# N32MC47x_DP47x register map
Vendor: Nsingtech Ltd.; File version: 1.0
Registers are 32-bit, read-write, reset 0x0 unless marked. A register's access mark holds for its fields unless they carry their own. Offsets are from the block's base; [hi:lo] are bit positions; lines under a group give offsets from that group; {n}, {i} and the like mark numbered series.

## ADC1 — Analog-to-digital converter
Base 0x4002B000
Same registers: ADC2 0x4002B400, ADC3 0x4002B800, ADC4 0x4002BC00
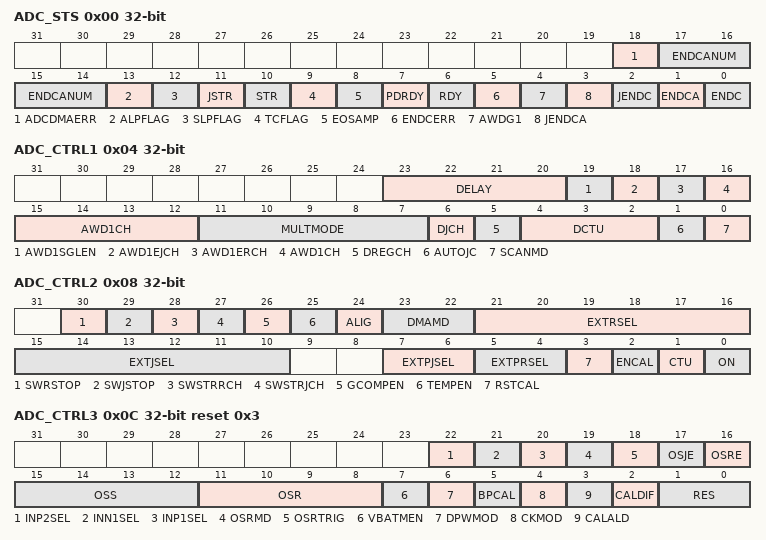
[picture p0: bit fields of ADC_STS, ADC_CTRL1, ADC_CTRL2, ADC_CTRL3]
0x00 ADC_STS — Status register
  [18] ADCDMAERR — ADC DMA error status flag
  [17:14] ENDCANUM ro — Regular channel current number
  [13] ALPFLAG — All-round data write to SRAM completion status flag
  [12] SLPFLAG — One-round data write to SRAM completion status flag
  [11] JSTR — Injected channel start flag
  [10] STR — Regular channel start flag
  [9] TCFLAG — Turncate flag
  [8] EOSAMP — Regular channel sample end flag
  [7] PDRDY — Power down ready
  [6] RDY — Ready
  [5] ENDCERR — End of conversion error flag
  [4] AWDG1 — Analog watchdog 1 flag
  [3] JENDCA — Any injected channel end of conversion
  [2] JENDC — Injected channel end of conversion
  [1] ENDCA — Any end of conversion flag
  [0] ENDC — End of conversion
0x04 ADC_CTRL1 — Control register 1
  [23:20] DELAY — Delay between 2 sampling phases in interleaved modes
  [19] AWD1SGLEN — Enable the watchdog 1 on a single channel in scan mode
  [18] AWD1EJCH — Analog watchdog 1 enable on injected channels
  [17] AWD1ERCH — Analog watchdog 1 enable on regular channels
  [16:12] AWD1CH — Analog watchdog channel select bits
  [11:7] MULTMODE — Multi ADC mode select
  [6] DJCH — Discontinuous mode on injected channels
  [5] DREGCH — Discontinuous mode on regular channels
  [4:2] DCTU — Discontinuous mode channel count
  [1] AUTOJC — Automatic injected group conversion
  [0] SCANMD — Scan mode
0x08 ADC_CTRL2 — Control register 2
  [30] SWRSTOP — Stop conversion of regular channels
  [29] SWJSTOP — Stop conversion of injected channels
  [28] SWSTRRCH — Start conversion of regular channels
  [27] SWSTRJCH — Start conversion of injected channels
  [26] GCOMPEN — Gain compensation mode
  [25] TEMPEN — Temperature sensor enable
  [24] ALIG — Data alignment
  [23:22] DMAMD — DMA mode
  [21:16] EXTRSEL — External event select for regular group
  [15:10] EXTJSEL — External event select for injected group
  [7:6] EXTPJSEL — External trigger polarity selection for injected channels
  [5:4] EXTPRSEL — External trigger polarity selection for regular channels
  [3] RSTCAL — Reset the calibration registers
  [2] ENCAL — A/D Calibration
  [1] CTU — Continuous conversion
  [0] ON — A/D converter ON/OFF
0x0C ADC_CTRL3 reset 0x3 — Control register 3
  [22] INP2SEL — ADC channel 2 positive end select
  [21] INN1SEL — ADC channel 1 negative end select
  [20] INP1SEL — ADC channel 1 positive end select
  [19] OSRMD — Regular channels oversample mode
  [18] OSRTRIG — Regular channels oversample trigger
  [17] OSJE — Injected channels oversample enable
  [16] OSRE — Regular channels oversample enable
  [15:12] OSS — Oversample data right shift bit width
  [11:8] OSR — Oversample rate times configuration
  [7] VBATMEN — Vbat monitor enable
  [6] DPWMOD — Deep Power Mode
  [5] BPCAL — Bypass calibration
  [4] CKMOD — Clock Mode
  [3] CALALD — Calibration auto load
  [2] CALDIF — Differential mode for calibration
  [1:0] RES — Data resolution
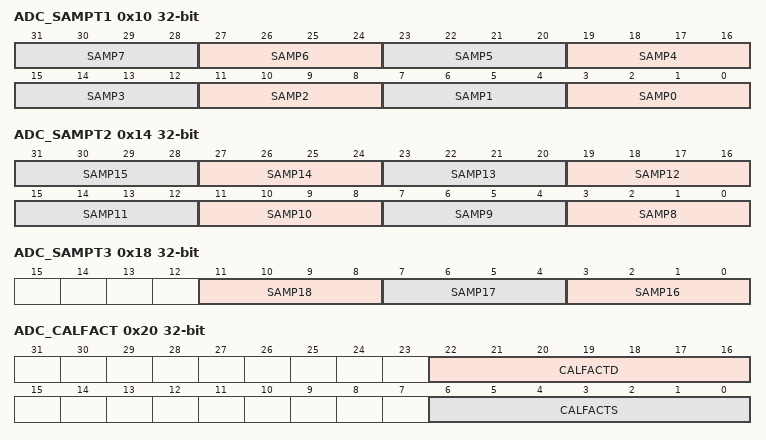
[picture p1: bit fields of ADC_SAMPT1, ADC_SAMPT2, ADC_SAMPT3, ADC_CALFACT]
0x10 ADC_SAMPT1 — Sample time register 1
  [4n+3:4n] SAMP{n} (n=0..7) — Channel {n} sampling time selection
0x14 ADC_SAMPT2 — Sample time register 2
  [4n-29:4n-32] SAMP{n} (n=8..15) — Channel {n} sampling time selection
0x18 ADC_SAMPT3 — Sample time register 3
  [11:8] SAMP18 — Channel 18 sampling time selection
  [7:4] SAMP17 — Channel 17 sampling time selection
  [3:0] SAMP16 — Channel 16 sampling time selection
0x1C ADC_DIFSEL — Differential mode selection register
  [18:1] DIFSEL — Differential mode for channels 18 to 1
0x20 ADC_CALFACT — Calibration factor register
  [22:16] CALFACTD — Calibration factors in differential mode
  [6:0] CALFACTS — Calibration factors in single-ended mode
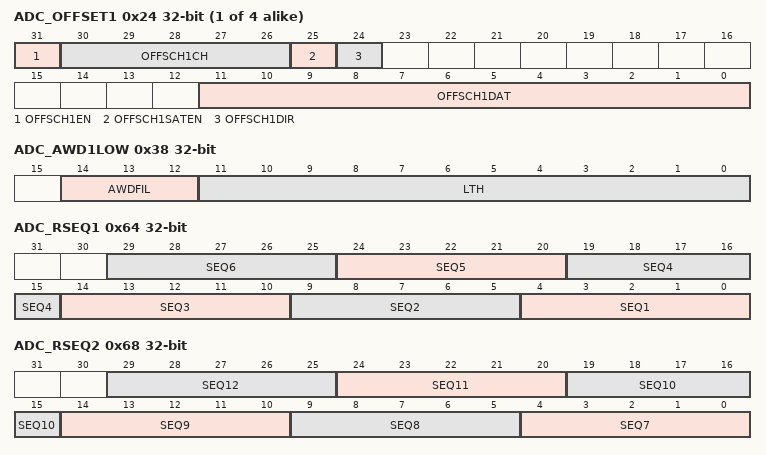
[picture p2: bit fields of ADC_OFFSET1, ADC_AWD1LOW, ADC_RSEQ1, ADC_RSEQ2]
{0x20+4i} ADC_OFFSET{i} (i=1..4) — Data offset register {i}
  [31] OFFSCH{i}EN — Offset channel {i} enable
  [30:26] OFFSCH{i}CH — Offset channel {i} selection
  [25] OFFSCH{i}SATEN — Saturation enable
  [24] OFFSCH{i}DIR — Offset direction
  [11:0] OFFSCH{i}DAT — Data offset for channel {i}
{0x2C+8i} ADC_AWD{i}HIGH reset 0xFFF (i=1..3) — Watchdog {i} high threshold register
  [11:0] HTH — Analog watchdog {i} high threshold
0x38 ADC_AWD1LOW — Watchdog 1 low threshold register
  [14:12] AWDFIL — Analog watchdog 1 filter value
  [11:0] LTH — Analog watchdog 1 low threshold
0x40 ADC_AWD2LOW — Watchdog 2 low threshold register
  [11:0] LTH — Analog watchdog 2 low threshold
0x48 ADC_AWD3LOW — Watchdog 3 low threshold register
  [11:0] LTH — Analog watchdog 3 low threshold
0x4C ADC_AWD2EN — Analog watchdog 2 enable register
  [18:0] AWD2EN — Analog watchdog 2 channel selection
0x50 ADC_AWD3EN — Analog watchdog 3 enable register
  [18:0] AWD3EN — Analog watchdog 3 channel selection
0x54 ADC_AWD2INTEN — Analog watchdog 2 interrupt enable register
  [18:0] AWD2INTEN — Analog watchdog 2 interrupt enable
0x58 ADC_AWD3INTEN — Analog watchdog 3 interrupt enable register
  [18:0] AWD3INTEN — Analog watchdog 3 interrupt enable
0x5C ADC_AWD2STS — Analog watchdog 2 status register
  [18:0] AWD2FLAG — Analog watchdog 2 status flag
0x60 ADC_AWD3STS — Analog watchdog 3 status register
  [18:0] AWD3FLAG — Analog watchdog 3 status flag
0x64 ADC_RSEQ1 — Regular sequence register 1
  [5n-1:5n-5] SEQ{n} (n=1..6) — {n}th conversion in regular sequence
0x68 ADC_RSEQ2 — Regular sequence register 2
  [5n-31:5n-35] SEQ{n} (n=7..12) — {n}th conversion in regular sequence
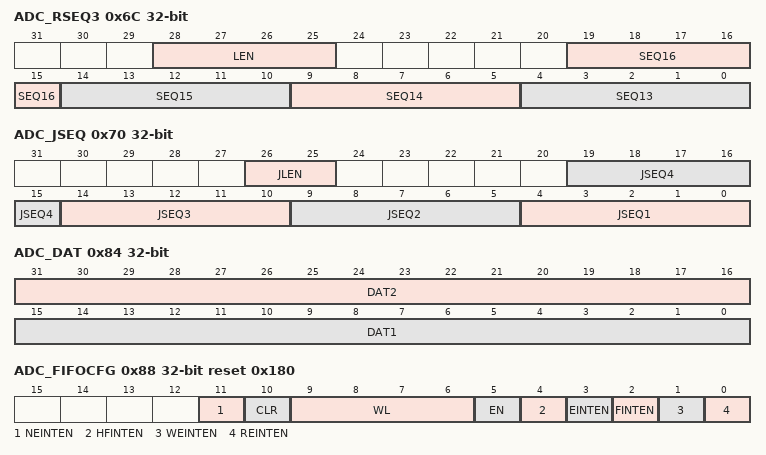
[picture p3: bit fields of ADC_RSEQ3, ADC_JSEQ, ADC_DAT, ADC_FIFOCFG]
0x6C ADC_RSEQ3 — Regular sequence register 3
  [28:25] LEN — Regular channel sequence length
  [5n-61:5n-65] SEQ{n} (n=13..16) — {n}th conversion in regular sequence
0x70 ADC_JSEQ — Injected sequence register
  [26:25] JLEN — Injected sequence length
  [19:15] JSEQ4 — 4th conversion in injected sequence
  [14:10] JSEQ3 — 3rd conversion in injected sequence
  [9:5] JSEQ2 — 2nd conversion in injected sequence
  [4:0] JSEQ1 — 1st conversion in injected sequence
{0x70+4i} ADC_JDAT{i} ro (i=1..4) — Injected data register {i}
  [15:0] JDAT — Injected data
0x84 ADC_DAT ro — Regular data register
  [31:16] DAT2 — 2nd data item of a pair of regular conversions
  [15:0] DAT1 — 1st data item of a pair of regular conversions
0x88 ADC_FIFOCFG reset 0x180 — FIFO configuration register
  [11] NEINTEN — FIFO non-empty interrupt enable
  [10] CLR — FIFO clear signal
  [9:6] WL — FIFO water level
  [5] EN — FIFO enable
  [4] HFINTEN — FIFO half-full interrupt enable
  [3] EINTEN — FIFO empty interrupt enable
  [2] FINTEN — FIFO full interrupt enable
  [1] WEINTEN — FIFO write error interrupt enable
  [0] REINTEN — FIFO read error interrupt enable
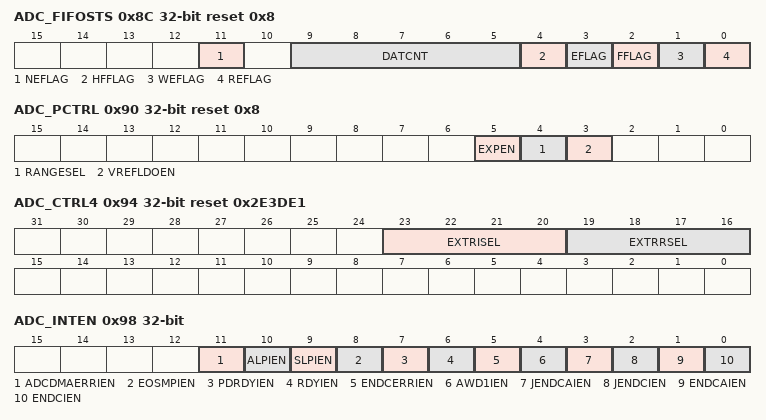
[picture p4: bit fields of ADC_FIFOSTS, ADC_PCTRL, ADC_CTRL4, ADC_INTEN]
0x8C ADC_FIFOSTS reset 0x8 — FIFO status register
  [11] NEFLAG — FIFO non-empty status
  [9:5] DATCNT ro — FIFO data count
  [4] HFFLAG — FIFO half-full status
  [3] EFLAG — FIFO empty status
  [2] FFLAG — FIFO full status
  [1] WEFLAG — FIFO write error status
  [0] REFLAG — FIFO read error status
0x90 ADC_PCTRL reset 0x8 — Power control register
  [5] EXPEN — External power supply enable
  [4] RANGESEL — LDO voltage range select
  [3] VREFLDOEN — LDO reference voltage select
0x94 ADC_CTRL4 reset 0x2E3DE1 — Control register 4
  [23:20] EXTRISEL — EXTI line select for injected trigger
  [19:16] EXTRRSEL — EXTI line select for regular trigger
0x98 ADC_INTEN — Interrupt enable register
  [11] ADCDMAERRIEN — ADC DMA error interrupt enable
  [10] ALPIEN — All-round data write to SRAM completion interrupt enable
  [9] SLPIEN — Single round data write to SRAM completion interrupt enable
  [8] EOSMPIEN — ADC sample done interrupt enable
  [7] PDRDYIEN — Power down ready interrupt enable
  [6] RDYIEN — Ready interrupt enable
  [5] ENDCERRIEN — ENDC error interrupt enable
  [4] AWD1IEN — Analog watchdog 1 interrupt enable
  [3] JENDCAIEN — Interrupt enable for any injected channels
  [2] JENDCIEN — Interrupt enable for injected channels
  [1] ENDCAIEN — Interrupt enable for any regular channels
  [0] ENDCIEN — Interrupt enable for ENDC
0x9C ADC_GCOMP — Gain compensation register
  [13:0] GCOMPDAT — Gain compensation coefficient
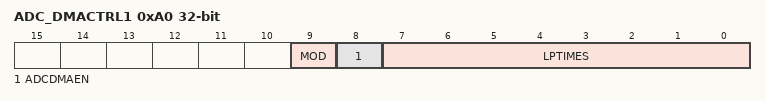
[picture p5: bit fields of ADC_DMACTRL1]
0xA0 ADC_DMACTRL1 — DMA control register 1
  [9] MOD — SRAM write address mapping type
  [8] ADCDMAEN — Dedicated DMA channel enable
  [7:0] LPTIMES — ADC regular channel repeat conversion count
0xA4 ADC_DMACTRL2 — DMA control register 2
  [31:0] STRADDR — Dedicated DMA start address
